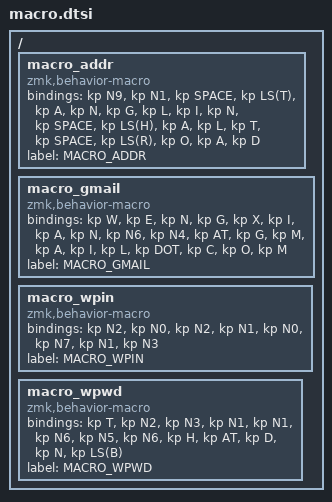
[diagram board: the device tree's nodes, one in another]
/ {
    macro_addr: macro_addr {
        compatible = "zmk,behavior-macro";
        #binding-cells = <0>;
        bindings = <&kp N9 &kp N1 &kp SPACE &kp LS(T) &kp A &kp N &kp G &kp L &kp I &kp N &kp SPACE &kp LS(H) &kp A &kp L &kp T &kp SPACE &kp LS(R) &kp O &kp A &kp D>;
        label = "MACRO_ADDR";
    };

    macro_gmail: macro_gmail {
        compatible = "zmk,behavior-macro";
        #binding-cells = <0>;
        bindings = <&kp W &kp E &kp N &kp G &kp X &kp I &kp A &kp N &kp N6 &kp N4 &kp AT &kp G &kp M &kp A &kp I &kp L &kp DOT &kp C &kp O &kp M>;
        label = "MACRO_GMAIL";
    };

    macro_wpin: macro_wpin {
        compatible = "zmk,behavior-macro";
        #binding-cells = <0>;
        bindings = <&kp N2 &kp N0 &kp N2 &kp N1 &kp N0 &kp N7 &kp N1 &kp N3>;
        label = "MACRO_WPIN";
    };

    macro_wpwd: macro_wpwd {
        compatible = "zmk,behavior-macro";
        #binding-cells = <0>;
        bindings = <&kp T &kp N2 &kp N3 &kp N1 &kp N1 &kp N6 &kp N5 &kp N6 &kp H &kp AT &kp D &kp N &kp LS(B)>;
        label = "MACRO_WPWD";
    };
};
